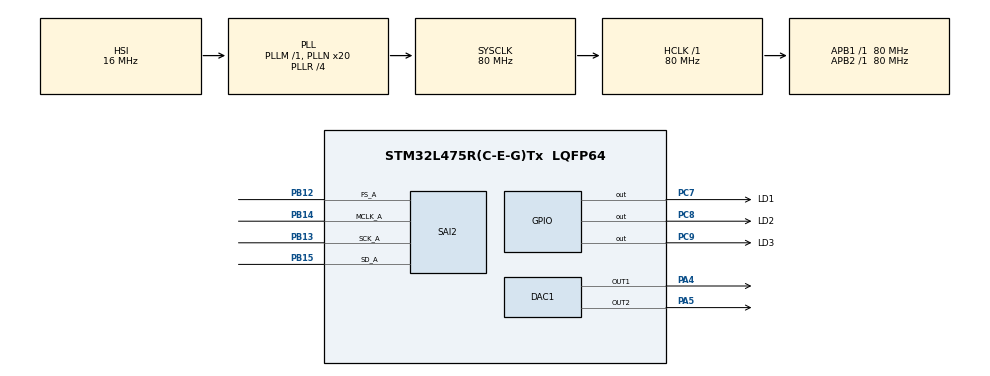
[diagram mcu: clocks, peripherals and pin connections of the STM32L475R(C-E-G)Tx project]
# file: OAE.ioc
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DAC1.DAC_Channel-DAC_OUT2=DAC_CHANNEL_2
DAC1.DAC_Trigger-DAC_OUT1=DAC_TRIGGER_T6_TRGO
DAC1.DAC_Trigger-DAC_OUT2=DAC_TRIGGER_T6_TRGO
Dma.DAC_CH1.0.Direction=DMA_MEMORY_TO_PERIPH
Dma.DAC_CH1.0.Instance=DMA1_Channel3
Dma.DAC_CH1.0.MemDataAlignment=DMA_MDATAALIGN_WORD
Dma.DAC_CH1.0.MemInc=DMA_MINC_ENABLE
Dma.DAC_CH1.0.Mode=DMA_CIRCULAR
Dma.DAC_CH1.0.PeriphDataAlignment=DMA_PDATAALIGN_WORD
Dma.DAC_CH1.0.PeriphInc=DMA_PINC_DISABLE
Dma.DAC_CH1.0.Priority=DMA_PRIORITY_HIGH
Dma.Request0=DAC_CH1
Dma.Request1=SAI2_A
Dma.SAI2_A.1.Direction=DMA_PERIPH_TO_MEMORY
Dma.SAI2_A.1.Instance=DMA2_Channel3
Dma.SAI2_A.1.MemDataAlignment=DMA_MDATAALIGN_HALFWORD
Dma.SAI2_A.1.MemInc=DMA_MINC_ENABLE
Dma.SAI2_A.1.Mode=DMA_CIRCULAR
Dma.SAI2_A.1.PeriphDataAlignment=DMA_PDATAALIGN_HALFWORD
Dma.SAI2_A.1.PeriphInc=DMA_PINC_DISABLE
Dma.SAI2_A.1.Priority=DMA_PRIORITY_HIGH
Mcu.Family=STM32L4
Mcu.Name=STM32L475R(C-E-G)Tx
Mcu.Package=LQFP64
NVIC.PriorityGroup=NVIC_PRIORITYGROUP_4
PA13\ (JTMS-SWDIO).Mode=Serial_Wire
PA13\ (JTMS-SWDIO).Signal=SYS_JTMS-SWDIO
PA14\ (JTCK-SWCLK).Mode=Serial_Wire
PA14\ (JTCK-SWCLK).Signal=SYS_JTCK-SWCLK
PA4.Signal=COMP_DAC11_group
PA5.Signal=COMP_DAC12_group
PB12.Mode=SAI_A_MasterWithClock
PB12.Signal=SAI2_FS_A
PB13.Mode=SAI_A_MasterWithClock
PB13.Signal=SAI2_SCK_A
PB14.Mode=SAI_A_MasterWithClock
PB14.Signal=SAI2_MCLK_A
PB15.Mode=SAI_A_MasterWithClock
PB15.Signal=SAI2_SD_A
PC7.GPIO_Label=LD1
PC7.Signal=GPIO_Output
PC8.GPIO_Label=LD2
PC8.Signal=GPIO_Output
PC9.GPIO_Label=LD3
PC9.Signal=GPIO_Output
PH0-OSC_IN\ (PH0).Mode=HSE-External-Oscillator
PH0-OSC_IN\ (PH0).Signal=RCC_OSC_IN
PH1-OSC_OUT\ (PH1).Mode=HSE-External-Oscillator
PH1-OSC_OUT\ (PH1).Signal=RCC_OSC_OUT
ProjectManager.HeapSize=0x200
ProjectManager.StackSize=0x400
ProjectManager.TargetToolchain=STM32CubeIDE
RCC.ADCFreq_Value=64000000
RCC.AHBFreq_Value=80000000
RCC.APB1Freq_Value=80000000
RCC.APB1TimFreq_Value=80000000
RCC.APB2Freq_Value=80000000
RCC.APB2TimFreq_Value=80000000
RCC.CK48CLockSelection=RCC_USBCLKSOURCE_MSI
RCC.CortexFreq_Value=80000000
RCC.HCLKFreq_Value=80000000
RCC.HSE_VALUE=8000000
RCC.HSI_VALUE=16000000
RCC.LSE_VALUE=32768
RCC.MSIClockRange=RCC_MSIRANGE_11
RCC.MSI_VALUE=48000000
RCC.PLLN=20
RCC.PLLR=RCC_PLLR_DIV4
RCC.PLLSAI2N=21
RCC.PLLSourceVirtual=RCC_PLLSOURCE_HSI
RCC.SAI2CLockSelection=RCC_SAI2CLKSOURCE_PLLSAI2
RCC.SYSCLKFreq_VALUE=80000000
RCC.SYSCLKSource=RCC_SYSCLKSOURCE_PLLCLK
RCC.USBFreq_Value=48000000
RCC.VCOOutputFreq_Value=320000000
SAI2.AudioFrequency-SAI_A_MasterWithClock=SAI_AUDIO_FREQUENCY_48K
SAI2.AudioMode-SAI_A_MasterWithClock=SAI_MODEMASTER_RX
SAI2.ErrorAudioFreq-SAI_A_MasterWithClock=-2.34 %
SAI2.InitProtocol-SAI_A_MasterWithClock=Enable
SAI2.Instance-SAI_A_MasterWithClock=SAI$Index_Block_A
SAI2.MClockEnable-SAI_A_MasterWithClock=SAI_MASTERCLOCK_ENABLE
SAI2.RealAudioFreq-SAI_A_MasterWithClock=46.875 KHz
SAI2.VirtualMode-SAI_A_MasterWithClock=VM_MASTER
SAI2.VirtualProtocol-SAI_A_BASIC=VM_BASIC_PROTOCOL
SH.COMP_DAC11_group.0=DAC1_OUT1,DAC_OUT1
SH.COMP_DAC12_group.0=DAC1_OUT2,DAC_OUT2
TIM6.Period=624
TIM6.TIM_MasterOutputTrigger=TIM_TRGO_UPDATE
VP_SAI2_VP_$IpInstance_SAIA_SAI_BASIC.Mode=SAI_A_BASIC
VP_TIM6_VS_ClockSourceINT.Mode=Enable_Timer
board=custom

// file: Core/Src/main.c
/* USER CODE BEGIN Header */
/**
  ******************************************************************************
  * @file           : main.c
  * @brief          : Main program body
  ******************************************************************************
  * @attention
  *
  * Copyright (c) 2023 STMicroelectronics.
  * All rights reserved.
  *
  * This software is licensed under terms that can be found in the LICENSE file
  * in the root directory of this software component.
  * If no LICENSE file comes with this software, it is provided AS-IS.
  *
  ******************************************************************************
  */
/* USER CODE END Header */
#include "main.h"

DAC_HandleTypeDef hdac1;
DMA_HandleTypeDef hdma_dac_ch1;

SAI_HandleTypeDef hsai_BlockA2;
DMA_HandleTypeDef hdma_sai2_a;

TIM_HandleTypeDef htim6;

void SystemClock_Config(void);
static void MX_GPIO_Init(void);
static void MX_DMA_Init(void);
static void MX_DAC1_Init(void);
static void MX_SAI2_Init(void);
static void MX_TIM6_Init(void);
/* USER CODE BEGIN PFP */
void app_setup(void);
void app_loop(void);
/* USER CODE END PFP */

int main(void)
{

  /* MCU Configuration--------------------------------------------------------*/

  /* Reset of all peripherals, Initializes the Flash interface and the Systick. */
  HAL_Init();

  /* Configure the system clock */
  SystemClock_Config();

  /* Initialize all configured peripherals */
  MX_GPIO_Init();
  MX_DMA_Init();
  MX_DAC1_Init();
  MX_SAI2_Init();
  MX_TIM6_Init();
  /* USER CODE BEGIN 2 */
  app_setup();
  /* USER CODE END 2 */

  /* Infinite loop */
  while (1)
  {

    /* USER CODE BEGIN 3 */
	  app_loop();
  }
  /* USER CODE END 3 */
}

void SystemClock_Config(void)
{
  RCC_OscInitTypeDef RCC_OscInitStruct = {0};
  RCC_ClkInitTypeDef RCC_ClkInitStruct = {0};

  /** Configure the main internal regulator output voltage
  */
  if (HAL_PWREx_ControlVoltageScaling(PWR_REGULATOR_VOLTAGE_SCALE1) != HAL_OK)
  {
    Error_Handler();
  }

  /** Initializes the RCC Oscillators according to the specified parameters
  * in the RCC_OscInitTypeDef structure.
  */
  RCC_OscInitStruct.OscillatorType = RCC_OSCILLATORTYPE_HSI;
  RCC_OscInitStruct.HSIState = RCC_HSI_ON;
  RCC_OscInitStruct.HSICalibrationValue = RCC_HSICALIBRATION_DEFAULT;
  RCC_OscInitStruct.PLL.PLLState = RCC_PLL_ON;
  RCC_OscInitStruct.PLL.PLLSource = RCC_PLLSOURCE_HSI;
  RCC_OscInitStruct.PLL.PLLM = 1;
  RCC_OscInitStruct.PLL.PLLN = 20;
  RCC_OscInitStruct.PLL.PLLP = RCC_PLLP_DIV7;
  RCC_OscInitStruct.PLL.PLLQ = RCC_PLLQ_DIV2;
  RCC_OscInitStruct.PLL.PLLR = RCC_PLLR_DIV4;
  if (HAL_RCC_OscConfig(&RCC_OscInitStruct) != HAL_OK)
  {
    Error_Handler();
  }

  /** Initializes the CPU, AHB and APB buses clocks
  */
  RCC_ClkInitStruct.ClockType = RCC_CLOCKTYPE_HCLK|RCC_CLOCKTYPE_SYSCLK
                              |RCC_CLOCKTYPE_PCLK1|RCC_CLOCKTYPE_PCLK2;
  RCC_ClkInitStruct.SYSCLKSource = RCC_SYSCLKSOURCE_PLLCLK;
  RCC_ClkInitStruct.AHBCLKDivider = RCC_SYSCLK_DIV1;
  RCC_ClkInitStruct.APB1CLKDivider = RCC_HCLK_DIV1;
  RCC_ClkInitStruct.APB2CLKDivider = RCC_HCLK_DIV1;

  if (HAL_RCC_ClockConfig(&RCC_ClkInitStruct, FLASH_LATENCY_4) != HAL_OK)
  {
    Error_Handler();
  }
}

static void MX_DAC1_Init(void)
{

  DAC_ChannelConfTypeDef sConfig = {0};

  /** DAC Initialization
  */
  hdac1.Instance = DAC1;
  if (HAL_DAC_Init(&hdac1) != HAL_OK)
  {
    Error_Handler();
  }

  /** DAC channel OUT1 config
  */
  sConfig.DAC_SampleAndHold = DAC_SAMPLEANDHOLD_DISABLE;
  sConfig.DAC_Trigger = DAC_TRIGGER_T6_TRGO;
  sConfig.DAC_OutputBuffer = DAC_OUTPUTBUFFER_ENABLE;
  sConfig.DAC_ConnectOnChipPeripheral = DAC_CHIPCONNECT_DISABLE;
  sConfig.DAC_UserTrimming = DAC_TRIMMING_FACTORY;
  if (HAL_DAC_ConfigChannel(&hdac1, &sConfig, DAC_CHANNEL_1) != HAL_OK)
  {
    Error_Handler();
  }

  /** DAC channel OUT2 config
  */
  if (HAL_DAC_ConfigChannel(&hdac1, &sConfig, DAC_CHANNEL_2) != HAL_OK)
  {
    Error_Handler();
  }

}

static void MX_SAI2_Init(void)
{

  hsai_BlockA2.Instance = SAI2_Block_A;
  hsai_BlockA2.Init.AudioMode = SAI_MODEMASTER_RX;
  hsai_BlockA2.Init.Synchro = SAI_ASYNCHRONOUS;
  hsai_BlockA2.Init.OutputDrive = SAI_OUTPUTDRIVE_DISABLE;
  hsai_BlockA2.Init.NoDivider = SAI_MASTERDIVIDER_ENABLE;
  hsai_BlockA2.Init.FIFOThreshold = SAI_FIFOTHRESHOLD_EMPTY;
  hsai_BlockA2.Init.AudioFrequency = SAI_AUDIO_FREQUENCY_48K;
  hsai_BlockA2.Init.SynchroExt = SAI_SYNCEXT_DISABLE;
  hsai_BlockA2.Init.MonoStereoMode = SAI_STEREOMODE;
  hsai_BlockA2.Init.CompandingMode = SAI_NOCOMPANDING;
  if (HAL_SAI_InitProtocol(&hsai_BlockA2, SAI_I2S_STANDARD, SAI_PROTOCOL_DATASIZE_16BIT, 2) != HAL_OK)
  {
    Error_Handler();
  }

}

static void MX_TIM6_Init(void)
{

  TIM_MasterConfigTypeDef sMasterConfig = {0};

  htim6.Instance = TIM6;
  htim6.Init.Prescaler = 0;
  htim6.Init.CounterMode = TIM_COUNTERMODE_UP;
  htim6.Init.Period = 624;
  htim6.Init.AutoReloadPreload = TIM_AUTORELOAD_PRELOAD_DISABLE;
  if (HAL_TIM_Base_Init(&htim6) != HAL_OK)
  {
    Error_Handler();
  }
  sMasterConfig.MasterOutputTrigger = TIM_TRGO_UPDATE;
  sMasterConfig.MasterSlaveMode = TIM_MASTERSLAVEMODE_DISABLE;
  if (HAL_TIMEx_MasterConfigSynchronization(&htim6, &sMasterConfig) != HAL_OK)
  {
    Error_Handler();
  }

}

static void MX_DMA_Init(void)
{

  /* DMA controller clock enable */
  __HAL_RCC_DMA1_CLK_ENABLE();
  __HAL_RCC_DMA2_CLK_ENABLE();

}

static void MX_GPIO_Init(void)
{
  GPIO_InitTypeDef GPIO_InitStruct = {0};

  /* GPIO Ports Clock Enable */
  __HAL_RCC_GPIOH_CLK_ENABLE();
  __HAL_RCC_GPIOA_CLK_ENABLE();
  __HAL_RCC_GPIOB_CLK_ENABLE();
  __HAL_RCC_GPIOC_CLK_ENABLE();

  /*Configure GPIO pin Output Level */
  HAL_GPIO_WritePin(GPIOC, LD1_Pin|LD2_Pin|LD3_Pin, GPIO_PIN_RESET);

  /*Configure GPIO pins : LD1_Pin LD2_Pin LD3_Pin */
  GPIO_InitStruct.Pin = LD1_Pin|LD2_Pin|LD3_Pin;
  GPIO_InitStruct.Mode = GPIO_MODE_OUTPUT_PP;
  GPIO_InitStruct.Pull = GPIO_NOPULL;
  GPIO_InitStruct.Speed = GPIO_SPEED_FREQ_LOW;
  HAL_GPIO_Init(GPIOC, &GPIO_InitStruct);

}

void Error_Handler(void)
{
  __disable_irq();
  while (1)
  {
  }
}
